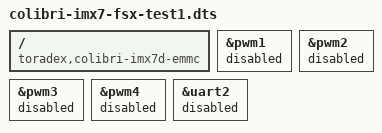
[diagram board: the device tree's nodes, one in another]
// FSx Datalogger Overlay

/dts-v1/;
/plugin/;

/ {
	compatible = "toradex,colibri-imx7d-emmc";
	fragment@0 {
		target = <&pwm1>;
		__overlay__ {
			status = "disabled";
		};
	};
	fragment@1 {
		target = <&pwm2>;
		__overlay__ {
			status = "disabled";
		};
	};
	fragment@2 {
		target = <&pwm3>;
		__overlay__{
			status = "disabled";
		};
	};
	fragment@3 {
		target = <&pwm4>;
		__overlay__{
			status = "disabled";
		};
	};
	fragment@4 {
		target = <&uart2>;
		__overlay__{
			/delete-property/fsl,uart-has-rtscts;
			status = "disabled";
		};
	};
};
